# PIC32CM5112GC00100 register map
Vendor: Microchip Technology; Series: PIC32CMGC00; File version: 0
CPU: CM23 r0p0, little endian, MPU, no FPU, 2 interrupt priority bits, 141 interrupts
Registers are 32-bit, read-write, reset 0x0 unless marked. A register's access mark holds for its fields unless they carry their own. Offsets are from the block's base; [hi:lo] are bit positions; lines under a group give offsets from that group; {n}, {i} and the like mark numbered series; 'fields as' and 'values as' point back to an identical list.

## HMATRIX2 — HSB Matrix
Base 0x44010000
{0x0+4i} MCFG[{i}] (i=0..5) reset 0x2 — Master Configuration
  [2:0] ULBT — Undefined Length Burst Type
    0=INFINITE (Infinite Length); 1=SINGLE (Single Access); 2=FOUR_BEAT (Four Beat Burst); 3=EIGHT_BEAT (Eight Beat Burst); 4=SIXTEEN_BEAT (Sixteen Beat Burst)
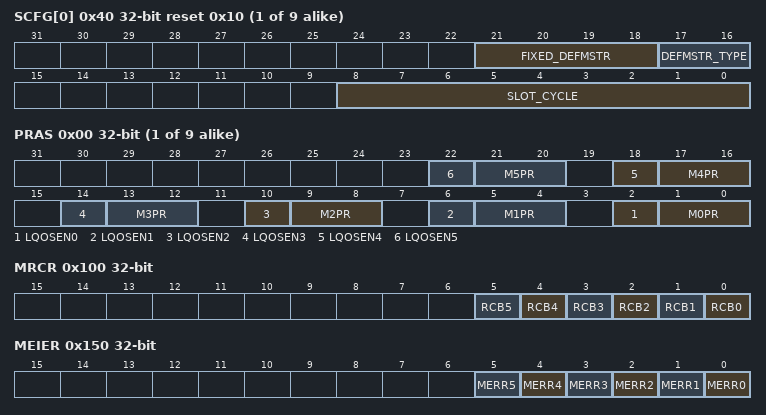
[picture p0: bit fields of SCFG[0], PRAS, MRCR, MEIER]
{0x40+4i} SCFG[{i}] (i=0..8) reset 0x10 — Slave Configuration
  [21:18] FIXED_DEFMSTR — Fixed Index of Default Master
  [17:16] DEFMSTR_TYPE — Default Master Type
    0=NO_DEFAULT (No Default Master. At the end of current slave access, if no other master request is pending, the slave is deconnected from all masters. This resusts in having a one cycle latency for the first transfer of a burst.); 1=LAST_DEFAULT (Last Default Master At the end of current slave access, if no other master request is pending, the slave stay connected with the last master havingaccessed it.This resusts in not having the one cycle latency when the last master re-trying access on the slave.); 2=FIXED_DEFAULT (Fixed Default Master At the end of current slave access, if no other master request is pending, the slave connects with fixed master which numberis in FIXED_DEFMSTR register.This resusts in not having the one cycle latency when the fixed master re-trying access on the slave.)
  [8:0] SLOT_CYCLE — Maximum Number of Allowed Cycles for a Burst
{0x80+8i} PRS[{i}] (i=0..8) group
  0x00 PRAS — Priority A for Slave
    [4n+2] LQOSEN{n} (n=0..5) — Latency Quality Of Service Enable for Master {n}
    [4n+1:4n] M{n}PR (n=0..5) — Master {n} Priority
0x100 MRCR — Master Remap Control
  [all] fields
    0=DIS (Disable remapped address decoding for master); 1=ENA (Enable remapped address decoding for master)
  [n] RCB{n} (n=0..5) — Remap Command Bit for Master {n}
{0x110+4i} SFR[{i}] (i=0..8) — Special Function
  [31:0] SFR — Special Function Register
0x150 MEIER wo — Master Error Interrupt Enable
  [n] MERR{n} (n=0..5) — Master {n} Access Error
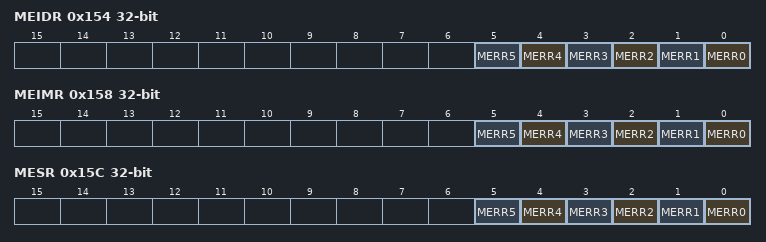
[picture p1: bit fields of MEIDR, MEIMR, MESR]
0x154 MEIDR wo — Master Error Interrupt Disable
  [n] MERR{n} (n=0..5) — Master {n} Access Error
0x158 MEIMR ro — Master Error Interrupt Mask
  [n] MERR{n} (n=0..5) — Master {n} Access Error
0x15C MESR ro — Master Error Status
  [n] MERR{n} (n=0..5) — Master {n} Access Error
{0x160+4i} MEAR[{i}] (i=0..5) ro — Master Error Address

## ICB — Implementation Control Block
Base 0xE000E000
0x04 ICTR ro — Interrupt Controller Type Register
  [3:0] INTLINESNUM — Interrupt line set number
0x08 ACTLR — Auxiliary Control Register

## MCLK — Polaris Main Clock Controller
Base 0x4400A000
0x00 INTENCLR — Interrupt Enable Clear Register
  [0] CKRDY — Clock Ready Interrupt Enable Clear
    0=The Clock Ready interrupt is disabled; 1=The Clock Ready interrupt is enabled
0x04 INTENSET — Interrupt Enable Set Register
  [0] CKRDY — Clock Ready Interrupt Enable Set
    values as INTENCLR.CKRDY
0x08 INTFLAG wo reset 0x1 — Interrupt Flag Status Register
  [0] CKRDY — Clock Ready Interrupt Flag
{0xC+4i} CLKDIV[{i}] (i=0..2) — Clock Divider Control n Register
  [7:0] DIV — Clock Domain n Division Factor
    1=Divide by 1; 2=Divide by 2; 4=Divide by 4; 8=Divide by 8; 16=Divide by 16; 32=Divide by 32; 64=Divide by 64; 128=Divide by 128
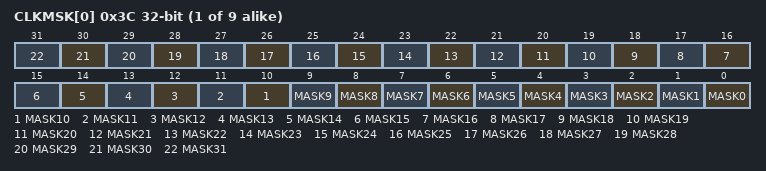
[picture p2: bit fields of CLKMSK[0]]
{0x3C+4i} CLKMSK[{i}] (i=0..8) — Peripheral Clock Enable Mask n Register
  [all] fields
    0=Peripheral clock mclk_clk_periph[n*32+x] stopped; 1=Peripheral clock mclk_clk_periph[n*32+x] enabled
  [n] MASK{n} (n=0..31) — Peripheral Clock Enable Mask

## MCRAMC — Multi-Channel RAM Controller
Base 0x4402C000
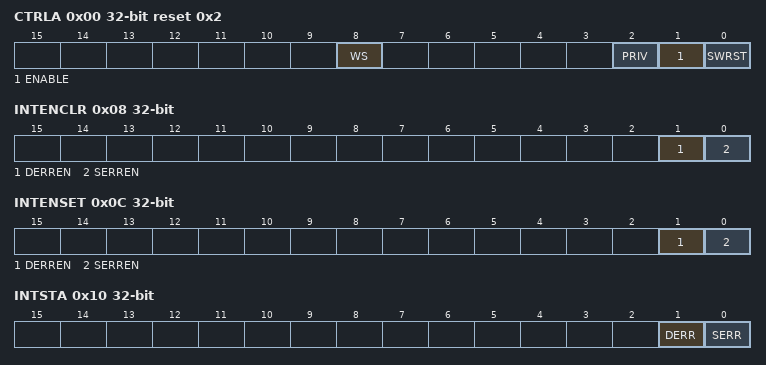
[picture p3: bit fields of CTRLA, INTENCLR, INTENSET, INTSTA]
0x00 CTRLA reset 0x2 — Control Enable A Register
  [8] WS — Wait State Enable
  [2] PRIV — Priviledged Access Enable
  [1] ENABLE — ECC Decoder Enable
    0=ECC decoding is disabled; 1=ECC decoding is enabled
  [0] SWRST — Software Reset
    0=No effect; 1=Reset the MCRAMC. A software-triggered hardware reset of the MCRAMC user interface is performed.
0x08 INTENCLR — Interrupt Enable Clear Register
  [1] DERREN — Double Bit Error Interrupt Enable, Clear
  [0] SERREN — Single Bit Error Interrupt Enable, Clear
0x0C INTENSET — Interrupt Enable Set Register
  [1] DERREN — Double Bit Error Interrupt Enable, Set
  [0] SERREN — Single Bit Error Interrupt Enable, Set
0x10 INTSTA — Interrupt Status Register
  [1] DERR — Double Bit Error
  [0] SERR — Single Bit Error
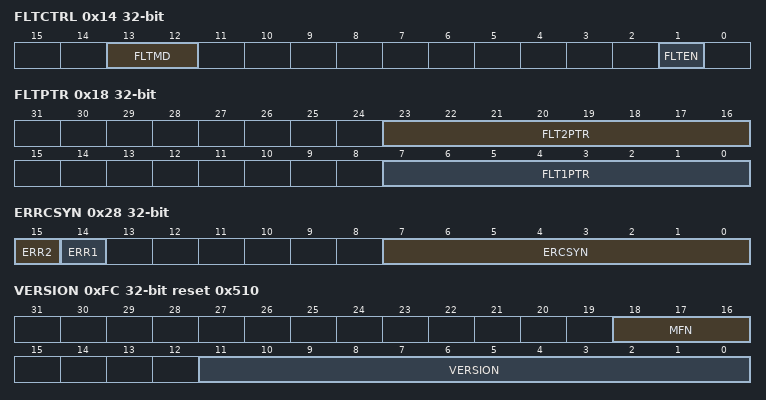
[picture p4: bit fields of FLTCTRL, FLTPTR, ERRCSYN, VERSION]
0x14 FLTCTRL — Fault Injection Control Register
  [13:12] FLTMD — Fault Injection Mode
  [1] FLTEN — Fault Injection Enabled
    0=Disables fault injection; 1=Enables fault injection at FLTADR address offset as selected by FLTMD and FLTxPTR
0x18 FLTPTR — Fault Injection Pointer Register
  [23:16] FLT2PTR — Double Fault Injection Bit Pointer
  [7:0] FLT1PTR — Single Fault Injection Bit Pointer
0x1C FLTADR — Fault Injection Address Register
  [23:0] FLTADR — Fault Address Offset
0x20 ERRCADR ro — Error Capture Address Register
  [23:0] ERCADR — ECC SECDED Error Capture Address
0x24 ERRCPAR ro — Error Capture Parity Register
  [7:0] ERCPAR — ECC SECDED Error Capture Parity
0x28 ERRCSYN ro — Error Capture Syndrome Register
  [15] ERR2 — ECC Double Bit Error
    0=Not a Double bit error; 1=Double bit error
  [14] ERR1 — ECC Single Bit Error
  [7:0] ERCSYN — ECC SECDED Error Capture Syndrome
    0=Not a Single bit error; 1=Single bit error
0xFC VERSION ro reset 0x510
  [18:16] MFN — Metal Fix Number
  [11:0] VERSION — MCRAMC Version

## Notices in the file
Copyright (c) 2025 Microchip Technology Inc.
SPDX-License-Identifier: Apache-2.0
Licensed under the Apache License, Version 2.0 (the "License");
you may not use this file except in compliance with the License.
You may obtain a copy of the License at
http://www.apache.org/licenses/LICENSE-2.0
Unless required by applicable law or agreed to in writing, software
distributed under the License is distributed on an "AS IS" BASIS,
WITHOUT WARRANTIES OR CONDITIONS OF ANY KIND, either express or implied.
See the License for the specific language governing permissions and
limitations under the License.
